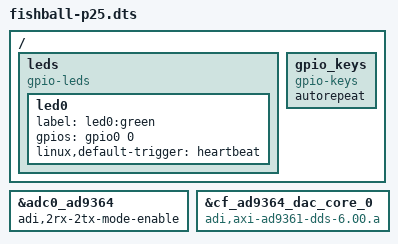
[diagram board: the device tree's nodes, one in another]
// SPDX-License-Identifier: GPL-2.0
/*
 * Fishball P25 Trunking Radio
 * Based on Fishball Z7020 (Zynq-7020 + AD9361)
 *
 * Same hardware as fishball.dts but with P25-specific FPGA nodes
 * (p25-core UIO + dibit/traffic DMA buffers instead of Maia SDR).
 */
/dts-v1/;
#include "fishball-p25.dtsi"


&adc0_ad9364 {
	// This property is controlled by u-boot environment.
	adi,2rx-2tx-mode-enable;
};

&cf_ad9364_dac_core_0 {
	/* This property is controlled by u-boot environment. */
	compatible = "adi,axi-ad9361-dds-6.00.a";
};

/ {
	leds {
		compatible = "gpio-leds";
		led0 {
			label = "led0:green";
			gpios = <&gpio0 0 0>;
			linux,default-trigger = "heartbeat";
		};
	};

	gpio_keys {
		compatible = "gpio-keys";
		#address-cells = <1>;
		#size-cells = <0>;
		autorepeat;
	};
};
